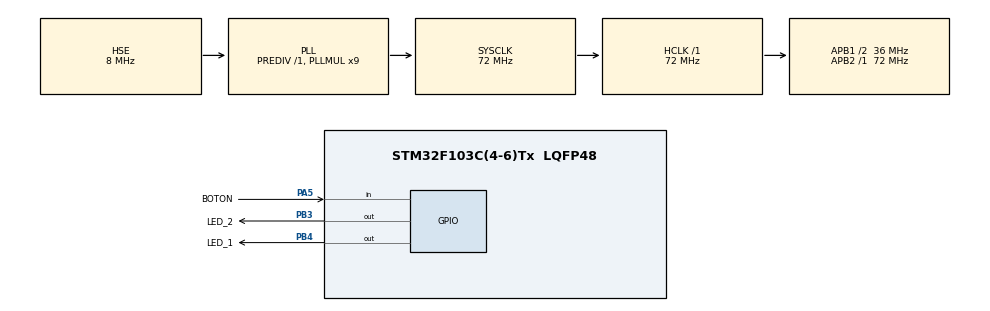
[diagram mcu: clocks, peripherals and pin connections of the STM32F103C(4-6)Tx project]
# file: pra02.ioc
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Mcu.Family=STM32F1
Mcu.Name=STM32F103C(4-6)Tx
Mcu.Package=LQFP48
NVIC.PriorityGroup=NVIC_PRIORITYGROUP_4
NVIC.TIM3_IRQn=true\:0\:0\:false\:false\:true\:true\:true\:true
PA13.Mode=Serial_Wire
PA13.Signal=SYS_JTMS-SWDIO
PA14.Mode=Serial_Wire
PA14.Signal=SYS_JTCK-SWCLK
PA5.GPIO_Label=BOTON
PA5.GPIO_PuPd=GPIO_PULLUP
PA5.Signal=GPIO_Input
PB3.GPIO_Label=LED_2
PB3.GPIO_PuPd=GPIO_NOPULL
PB3.Signal=GPIO_Output
PB4.GPIO_Label=LED_1
PB4.GPIO_PuPd=GPIO_NOPULL
PB4.Signal=GPIO_Output
PD0-OSC_IN.Mode=HSE-External-Oscillator
PD0-OSC_IN.Signal=RCC_OSC_IN
PD1-OSC_OUT.Mode=HSE-External-Oscillator
PD1-OSC_OUT.Signal=RCC_OSC_OUT
ProjectManager.HeapSize=0x200
ProjectManager.StackSize=0x400
ProjectManager.TargetToolchain=STM32CubeIDE
RCC.AHBFreq_Value=72000000
RCC.APB1CLKDivider=RCC_HCLK_DIV2
RCC.APB1Freq_Value=36000000
RCC.APB1TimFreq_Value=72000000
RCC.APB2Freq_Value=72000000
RCC.APB2TimFreq_Value=72000000
RCC.HCLKFreq_Value=72000000
RCC.PLLMUL=RCC_PLL_MUL9
RCC.PLLSourceVirtual=RCC_PLLSOURCE_HSE
RCC.SYSCLKFreq_VALUE=72000000
RCC.SYSCLKSource=RCC_SYSCLKSOURCE_PLLCLK
RCC.USBFreq_Value=72000000
TIM3.CounterMode=TIM_COUNTERMODE_UP
TIM3.Period=100-1
TIM3.Prescaler=7200-1
VP_TIM3_VS_ClockSourceINT.Mode=Internal
board=custom

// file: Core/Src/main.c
/* USER CODE BEGIN Header */
/**
 ******************************************************************************
 * @file           : main.c
 * @brief          : Main program body
 ******************************************************************************
 * @attention
 *
 * Copyright (c) 2023 STMicroelectronics.
 * All rights reserved.
 *
 * This software is licensed under terms that can be found in the LICENSE file
 * in the root directory of this software component.
 * If no LICENSE file comes with this software, it is provided AS-IS.
 *
 ******************************************************************************
 */
/* USER CODE END Header */
#include "main.h"

TIM_HandleTypeDef htim3;

/* USER CODE BEGIN PV */
volatile char presionada = 0, bandera = 0;
/* USER CODE END PV */

void SystemClock_Config(void);
static void MX_GPIO_Init(void);
static void MX_TIM3_Init(void);

/* USER CODE BEGIN 0 */
void series() {
	static uint32_t diezMilis = 0;
	static char etapa = 0;

	switch (etapa) {
	case 0:
		if (HAL_GPIO_ReadPin(BOTON_GPIO_Port, BOTON_Pin)==0) {
							etapa=1;
							diezMilis++;
							/*if (etapa>3) {
								etapa=0;

							}*/
						}
		if (diezMilis>0 &&diezMilis<5000) {
			HAL_GPIO_WritePin(LED_1_GPIO_Port, LED_1_Pin, SET);
		}

		if (diezMilis>5000 &&diezMilis<8000) {
				HAL_GPIO_WritePin(LED_1_GPIO_Port, LED_1_Pin, RESET);
			}
		diezMilis++;
	}
		/*if (0 == HAL_GPIO_ReadPin(BOTON_GPIO_Port, BOTON_Pin)) {
			diezMilis++;
			//HAL_GPIO_WritePin(LED_1_GPIO_Port, LED_1_Pin, 1);
			//diezMilis=0;
		}
		if (5000 == diezMilis) {
			//Encienda el LED 1
			HAL_GPIO_WritePin(LED_1_GPIO_Port, LED_1_Pin, 1);
			//este apagado el LED 2
			HAL_GPIO_WritePin(LED_2_GPIO_Port, LED_2_Pin, 0);
		}
		if (3000 == diezMilis) {
			HAL_GPIO_WritePin(LED_1_GPIO_Port, LED_1_Pin, 0);
			HAL_GPIO_WritePin(LED_2_GPIO_Port, LED_2_Pin, 0);
			etapa = 1;
		}
		break;

	case 2:
			  if(0==HAL_GPIO_ReadPin(BOTON_GPIO_Port, BOTON_Pin)){

				  HAL_GPIO_WritePin(LED_1_GPIO_Port, LED_1_Pin, 0);
				  etapa=3;
			  }
			  if(4500==diezMilis){
				  if(1==HAL_GPIO_ReadPin(BOTON_GPIO_Port,BOTON_Pin)){

					  etapa=0;
					  diezMilis=0;

					  HAL_GPIO_WritePin(LED_1_GPIO_Port, LED_1_Pin, 0);

					  HAL_GPIO_WritePin(LED_2_GPIO_Port, LED_2_Pin, 1);
				  }
			  }
			  break;
		case 3:
			  if(1==HAL_GPIO_ReadPin(BOTON_GPIO_Port, BOTON_Pin)){
				  //si no hay flama
				  etapa=0;
				  diezMilis=0;
				  //Apaga el Generador de chispa
				  HAL_GPIO_WritePin(LED_1_GPIO_Port, LED_1_Pin, 0);
				  //cierra la valvula de gas
				  HAL_GPIO_WritePin(LED_2_GPIO_Port, LED_2_Pin, 1);
			  }
			  break;
		//HAL_GPIO_TogglePin(LED_1_GPIO_Port, LED_1_Pin);

	}
	//HAL_GPIO_TogglePin(LED_1_GPIO_Port, LED_1_Pin);
	//diezMilis++;*/
}

/*void noRebotes() {
	static char ceros = 0, unos = 0;
	static char etapa = 0;
	if (HAL_GPIO_ReadPin(BOTON_GPIO_Port, BOTON_Pin) == 0) {
		ceros++;
		unos = 0;
	} else {
		ceros = 0;
		unos++;
	}

	switch (etapa) {
	case 0:				//espera a detectar un nivel alto estable
		if (3 == unos)
			etapa = 1;
		break;
	case 1:				//espera a detectar un nivel bajo estable
		if (3 == ceros) {
			etapa = 0;
			presionada = 1;
		}
		break;
	}
}*/
/* USER CODE END 0 */

int main(void)
{

  /* MCU Configuration--------------------------------------------------------*/

  /* Reset of all peripherals, Initializes the Flash interface and the Systick. */
  HAL_Init();

  /* Configure the system clock */
  SystemClock_Config();

  /* Initialize all configured peripherals */
  MX_GPIO_Init();
  MX_TIM3_Init();
  /* USER CODE BEGIN 2 */
		HAL_TIM_Base_Start_IT(&htim3);
  /* USER CODE END 2 */

  /* Infinite loop */
  /* USER CODE BEGIN WHILE */
		while (1) {
			//series();
			//noRebotes();
			//while (0 == bandera)
				//;
			bandera = 0;
    /* USER CODE END WHILE */

		}
}

void SystemClock_Config(void)
{
  RCC_OscInitTypeDef RCC_OscInitStruct = {0};
  RCC_ClkInitTypeDef RCC_ClkInitStruct = {0};

  /** Initializes the RCC Oscillators according to the specified parameters
  * in the RCC_OscInitTypeDef structure.
  */
  RCC_OscInitStruct.OscillatorType = RCC_OSCILLATORTYPE_HSE;
  RCC_OscInitStruct.HSEState = RCC_HSE_ON;
  RCC_OscInitStruct.HSEPredivValue = RCC_HSE_PREDIV_DIV1;
  RCC_OscInitStruct.HSIState = RCC_HSI_ON;
  RCC_OscInitStruct.PLL.PLLState = RCC_PLL_ON;
  RCC_OscInitStruct.PLL.PLLSource = RCC_PLLSOURCE_HSE;
  RCC_OscInitStruct.PLL.PLLMUL = RCC_PLL_MUL9;
  if (HAL_RCC_OscConfig(&RCC_OscInitStruct) != HAL_OK)
  {
    Error_Handler();
  }

  /** Initializes the CPU, AHB and APB buses clocks
  */
  RCC_ClkInitStruct.ClockType = RCC_CLOCKTYPE_HCLK|RCC_CLOCKTYPE_SYSCLK
                              |RCC_CLOCKTYPE_PCLK1|RCC_CLOCKTYPE_PCLK2;
  RCC_ClkInitStruct.SYSCLKSource = RCC_SYSCLKSOURCE_PLLCLK;
  RCC_ClkInitStruct.AHBCLKDivider = RCC_SYSCLK_DIV1;
  RCC_ClkInitStruct.APB1CLKDivider = RCC_HCLK_DIV2;
  RCC_ClkInitStruct.APB2CLKDivider = RCC_HCLK_DIV1;

  if (HAL_RCC_ClockConfig(&RCC_ClkInitStruct, FLASH_LATENCY_2) != HAL_OK)
  {
    Error_Handler();
  }
}

static void MX_TIM3_Init(void)
{

  TIM_ClockConfigTypeDef sClockSourceConfig = {0};
  TIM_MasterConfigTypeDef sMasterConfig = {0};

  htim3.Instance = TIM3;
  htim3.Init.Prescaler = 7200-1;
  htim3.Init.CounterMode = TIM_COUNTERMODE_UP;
  htim3.Init.Period = 100-1;
  htim3.Init.ClockDivision = TIM_CLOCKDIVISION_DIV1;
  htim3.Init.AutoReloadPreload = TIM_AUTORELOAD_PRELOAD_DISABLE;
  if (HAL_TIM_Base_Init(&htim3) != HAL_OK)
  {
    Error_Handler();
  }
  sClockSourceConfig.ClockSource = TIM_CLOCKSOURCE_INTERNAL;
  if (HAL_TIM_ConfigClockSource(&htim3, &sClockSourceConfig) != HAL_OK)
  {
    Error_Handler();
  }
  sMasterConfig.MasterOutputTrigger = TIM_TRGO_RESET;
  sMasterConfig.MasterSlaveMode = TIM_MASTERSLAVEMODE_DISABLE;
  if (HAL_TIMEx_MasterConfigSynchronization(&htim3, &sMasterConfig) != HAL_OK)
  {
    Error_Handler();
  }

}

static void MX_GPIO_Init(void)
{
  GPIO_InitTypeDef GPIO_InitStruct = {0};

  /* GPIO Ports Clock Enable */
  __HAL_RCC_GPIOD_CLK_ENABLE();
  __HAL_RCC_GPIOA_CLK_ENABLE();
  __HAL_RCC_GPIOB_CLK_ENABLE();

  /*Configure GPIO pin Output Level */
  HAL_GPIO_WritePin(GPIOB, LED_2_Pin|LED_1_Pin, GPIO_PIN_RESET);

  /*Configure GPIO pin : BOTON_Pin */
  GPIO_InitStruct.Pin = BOTON_Pin;
  GPIO_InitStruct.Mode = GPIO_MODE_INPUT;
  GPIO_InitStruct.Pull = GPIO_PULLUP;
  HAL_GPIO_Init(BOTON_GPIO_Port, &GPIO_InitStruct);

  /*Configure GPIO pins : LED_2_Pin LED_1_Pin */
  GPIO_InitStruct.Pin = LED_2_Pin|LED_1_Pin;
  GPIO_InitStruct.Mode = GPIO_MODE_OUTPUT_PP;
  GPIO_InitStruct.Pull = GPIO_NOPULL;
  GPIO_InitStruct.Speed = GPIO_SPEED_FREQ_LOW;
  HAL_GPIO_Init(GPIOB, &GPIO_InitStruct);

}

void Error_Handler(void)
{
  /* USER CODE BEGIN Error_Handler_Debug */
		/* User can add his own implementation to report the HAL error return state */
		__disable_irq();
		while (1) {
			series();
		}
  /* USER CODE END Error_Handler_Debug */
}
